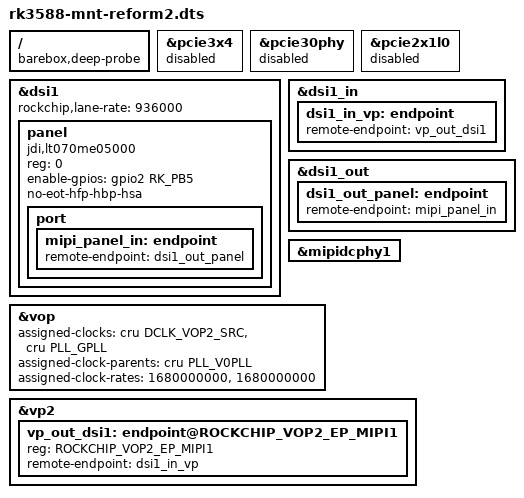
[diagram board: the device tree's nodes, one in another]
// SPDX-License-Identifier: (GPL-2.0+ OR MIT)
/*
 * Copyright (c) 2021 Rockchip Electronics Co., Ltd.
 * Copyright (c) 2024 MNT Research GmbH
 *
 */

/dts-v1/;

#include <arm64/rockchip/rk3588-mnt-reform2.dts>
#include "rk3588.dtsi"
#include <dt-bindings/pinctrl/rockchip.h>
#include <dt-bindings/gpio/gpio.h>

/ {
	barebox,deep-probe;
};

&pcie3x4 {
	/* Does not work in barebox (missing phy driver) */
	status = "disabled";
};

&pcie30phy {
	status = "disabled";
};

&pcie2x1l0 {
	/* Does not work in barebox */
	status = "disabled";
};

&dsi1 {
	status = "okay";
	rockchip,lane-rate = <936000>;
	#address-cells = <1>;
	#size-cells = <0>;

	panel {
		compatible = "jdi,lt070me05000";
		reg = <0>;

		// reset is driven by rp2040
		// dcdc en is also driven by rp2040
		// actually backlight enable
		enable-gpios = <&gpio2 RK_PB5 GPIO_ACTIVE_HIGH>;
		no-eot-hfp-hbp-hsa;

		port {
			mipi_panel_in: endpoint {
				remote-endpoint = <&dsi1_out_panel>;
			};
		};
	};
};

&dsi1_in {
	dsi1_in_vp: endpoint {
		remote-endpoint = <&vp_out_dsi1>;
	};
};

&dsi1_out {
	dsi1_out_panel: endpoint {
		remote-endpoint = <&mipi_panel_in>;
	};
};

&mipidcphy1 {
	status = "okay";
};

&vop {
	assigned-clocks = <&cru DCLK_VOP2_SRC>, <&cru PLL_GPLL>;
	assigned-clock-parents = <&cru PLL_V0PLL>;
	assigned-clock-rates = <1680000000>, <1680000000>;

	status = "okay";
};

&vp2 {
	vp_out_dsi1: endpoint@ROCKCHIP_VOP2_EP_MIPI1 {
		reg = <ROCKCHIP_VOP2_EP_MIPI1>;
		remote-endpoint = <&dsi1_in_vp>;
	};
};
